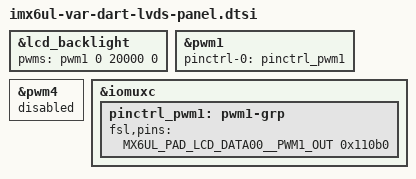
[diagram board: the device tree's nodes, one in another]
// SPDX-License-Identifier: GPL-2.0+
/*
 * LVDS panel backlight wiring for DART-6UL on VAR-6ULCustomBoard.
 *
 * Copyright (C) 2026 Variscite Ltd. - https://www.variscite.com
 */

#include "imx6ul-var-som-lvds-panel.dtsi"

&lcd_backlight {
	pwms = <&pwm1 0 20000 0>;
};

&pwm1 {
	pinctrl-names = "default";
	pinctrl-0 = <&pinctrl_pwm1>;
	status = "okay";
};

&pwm4 {
	status = "disabled";
};

&iomuxc {
	pinctrl_pwm1: pwm1-grp {
		fsl,pins = <
			MX6UL_PAD_LCD_DATA00__PWM1_OUT		0x110b0
		>;
	};
};
